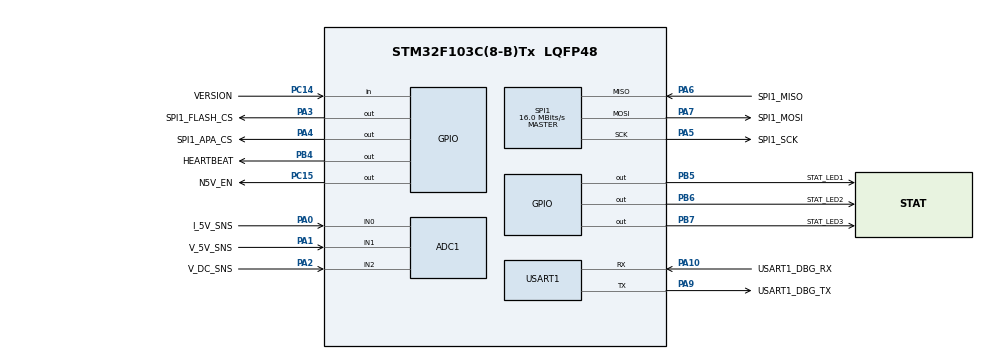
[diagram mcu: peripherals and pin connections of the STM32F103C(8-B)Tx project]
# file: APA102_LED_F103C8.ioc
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Mcu.Family=STM32F1
Dma.SPI1_TX.1.Priority=DMA_PRIORITY_HIGH
PA6.Mode=Full_Duplex_Master
SPI1.VirtualType=VM_MASTER
PA14.GPIO_Label=SWD_CLK
PA3.GPIO_PuPd=GPIO_NOPULL
Dma.SPI1_TX.1.PeriphInc=DMA_PINC_DISABLE
PA6.GPIO_Label=SPI1_MISO
PB6.GPIO_Label=STAT_LED2
PA3.GPIO_Speed=GPIO_SPEED_FREQ_HIGH
PC15-OSC32_OUT.GPIO_Label=N5V_EN
RCC.SYSCLKSource=RCC_SYSCLKSOURCE_PLLCLK
ProjectManager.StackSize=0x400
NVIC.DMA1_Channel3_IRQn=true\:0\:0\:false\:false\:true\:false\:true
Dma.SPI1_RX.0.Direction=DMA_PERIPH_TO_MEMORY
SPI1.Direction=SPI_DIRECTION_2LINES
RCC.HCLKFreq_Value=64000000
RCC.APB2TimFreq_Value=64000000
PB6.Signal=GPIO_Output
ADC1.Channel-2\#ChannelRegularConversion=ADC_CHANNEL_2
PB5.PinState=GPIO_PIN_SET
SPI1.CalculateBaudRate=16.0 MBits/s
RCC.AHBFreq_Value=64000000
Dma.SPI1_TX.1.PeriphDataAlignment=DMA_PDATAALIGN_BYTE
ADC1.Channel-0\#ChannelRegularConversion=ADC_CHANNEL_0
PA4.GPIO_PuPd=GPIO_NOPULL
PB3.Mode=Trace_Asynchronous_SW
RCC.PLLMUL=RCC_PLL_MUL16
PA4.GPIO_Speed=GPIO_SPEED_FREQ_HIGH
Dma.SPI1_RX.0.PeriphInc=DMA_PINC_DISABLE
ADC1.Rank-2\#ChannelRegularConversion=3
Dma.ADC1.2.MemDataAlignment=DMA_MDATAALIGN_HALFWORD
Dma.SPI1_TX.1.Mode=DMA_NORMAL
PA14.Mode=Trace_Asynchronous_SW
PA10.GPIO_Label=USART1_DBG_RX
Dma.ADC1.2.Direction=DMA_PERIPH_TO_MEMORY
PB7.Signal=GPIO_Output
PC15-OSC32_OUT.PinState=GPIO_PIN_SET
ADC1.SamplingTime-0\#ChannelRegularConversion=ADC_SAMPLETIME_55CYCLES_5
PB7.PinState=GPIO_PIN_SET
PB7.GPIO_Label=STAT_LED3
Mcu.Package=LQFP48
PA6.Signal=SPI1_MISO
PA2.GPIO_Label=V_DC_SNS
PB6.GPIO_ModeDefaultOutputPP=GPIO_MODE_OUTPUT_PP
PA10.Signal=USART1_RX
PA4.GPIO_ModeDefaultOutputPP=GPIO_MODE_OUTPUT_PP
PB5.GPIO_Speed=GPIO_SPEED_FREQ_MEDIUM
PB5.GPIO_Label=STAT_LED1
Dma.Request2=ADC1
Dma.Request1=SPI1_TX
RCC.APB1TimFreq_Value=64000000
PC14-OSC32_IN.GPIO_Label=VERSION
PC15-OSC32_OUT.GPIO_Speed=GPIO_SPEED_FREQ_MEDIUM
NVIC.USART1_IRQn=true\:0\:0\:false\:false\:true\:true\:true
Dma.Request0=SPI1_RX
SPI1.BaudRatePrescaler=SPI_BAUDRATEPRESCALER_4
PB4.PinState=GPIO_PIN_SET
PA4.GPIO_Label=SPI1_APA_CS
Dma.SPI1_TX.1.Instance=DMA1_Channel3
PB4.Signal=GPIO_Output
Dma.ADC1.2.Mode=DMA_NORMAL
PB4.GPIO_ModeDefaultOutputPP=GPIO_MODE_OUTPUT_PP
PA3.Signal=GPIO_Output
PA5.Mode=Full_Duplex_Master
PB7.GPIO_Speed=GPIO_SPEED_FREQ_MEDIUM
PB3.GPIO_Label=SWD_O
PB7.GPIO_PuPd=GPIO_NOPULL
PB5.GPIO_ModeDefaultOutputPP=GPIO_MODE_OUTPUT_PP
Dma.SPI1_TX.1.MemInc=DMA_MINC_ENABLE
PA3.GPIO_ModeDefaultOutputPP=GPIO_MODE_OUTPUT_PP
ADC1.Rank-0\#ChannelRegularConversion=1
PA7.Mode=Full_Duplex_Master
PA10.Mode=Asynchronous
SH.SharedAnalog_PA0.0=GPIO_Analog
SH.SharedAnalog_PA0.1=ADC1_IN0,IN0
PA9.GPIO_Label=USART1_DBG_TX
Dma.ADC1.2.PeriphDataAlignment=DMA_PDATAALIGN_HALFWORD
PB6.GPIO_PuPd=GPIO_NOPULL
Dma.SPI1_RX.0.Mode=DMA_NORMAL
RCC.APB1CLKDivider=RCC_HCLK_DIV2
PC14-OSC32_IN.Signal=GPIO_Input
Dma.SPI1_TX.1.Direction=DMA_MEMORY_TO_PERIPH
ADC1.SamplingTime-2\#ChannelRegularConversion=ADC_SAMPLETIME_55CYCLES_5
PA0-WKUP.GPIO_Label=I_5V_SNS
PA0-WKUP.Signal=SharedAnalog_PA0
RCC.ADCPresc=RCC_ADCPCLK2_DIV6
PA13.Signal=SYS_JTMS-SWDIO
PA9.Mode=Asynchronous
Dma.SPI1_TX.1.MemDataAlignment=DMA_MDATAALIGN_BYTE
Dma.ADC1.2.MemInc=DMA_MINC_ENABLE
PA4.PinState=GPIO_PIN_SET
NVIC.DMA1_Channel2_IRQn=true\:0\:0\:false\:false\:true\:false\:true
ProjectManager.TargetToolchain=STM32CubeIDE
PA9.Signal=USART1_TX
ADC1.Channel-1\#ChannelRegularConversion=ADC_CHANNEL_1
PB4.GPIO_PuPd=GPIO_NOPULL
RCC.USBFreq_Value=64000000
PC15-OSC32_OUT.Signal=GPIO_Output
PA1.Signal=SharedAnalog_PA1
PA5.Signal=SPI1_SCK
board=custom
PB4.GPIO_Speed=GPIO_SPEED_FREQ_MEDIUM
RCC.APB2Freq_Value=64000000
PB4.GPIO_Label=HEARTBEAT
SPI1.Mode=SPI_MODE_MASTER
PB7.GPIO_ModeDefaultOutputPP=GPIO_MODE_OUTPUT_PP
Dma.SPI1_RX.0.Instance=DMA1_Channel2
SH.SharedAnalog_PA2.0=GPIO_Analog
SH.SharedAnalog_PA2.1=ADC1_IN2,IN2
PA1.GPIO_Label=V_5V_SNS
Dma.SPI1_RX.0.PeriphDataAlignment=DMA_PDATAALIGN_BYTE
Dma.SPI1_RX.0.MemDataAlignment=DMA_MDATAALIGN_BYTE
ADC1.NbrOfConversion=3
PA13.Mode=Trace_Asynchronous_SW
Mcu.Name=STM32F103C(8-B)Tx
Dma.SPI1_RX.0.MemInc=DMA_MINC_ENABLE
PA2.Signal=SharedAnalog_PA2
PA13.GPIO_Label=SWD_IO
Dma.ADC1.2.Instance=DMA1_Channel1
PB3.Signal=SYS_JTDO-TRACESWO
PA4.Signal=GPIO_Output
ADC1.SamplingTime-1\#ChannelRegularConversion=ADC_SAMPLETIME_55CYCLES_5
RCC.SYSCLKFreq_VALUE=64000000
Dma.ADC1.2.Priority=DMA_PRIORITY_MEDIUM
PB5.Signal=GPIO_Output
PA7.GPIO_Label=SPI1_MOSI
ADC1.master=1
PA5.GPIO_Label=SPI1_SCK
Dma.ADC1.2.PeriphInc=DMA_PINC_DISABLE
PB5.GPIO_PuPd=GPIO_NOPULL
USART1.VirtualMode=VM_ASYNC
PB6.PinState=GPIO_PIN_SET
ADC1.Rank-1\#ChannelRegularConversion=2
PA14.Signal=SYS_JTCK-SWCLK
ProjectManager.HeapSize=0x200
Dma.SPI1_RX.0.Priority=DMA_PRIORITY_HIGH
SH.SharedAnalog_PA1.1=ADC1_IN1,IN1
NVIC.PriorityGroup=NVIC_PRIORITYGROUP_4
SH.SharedAnalog_PA1.0=GPIO_Analog
ADC1.NbrOfConversionFlag=1
PA3.PinState=GPIO_PIN_SET
PC14-OSC32_IN.GPIO_PuPd=GPIO_PULLDOWN
NVIC.DMA1_Channel1_IRQn=true\:0\:0\:false\:false\:true\:false\:true
PB6.GPIO_Speed=GPIO_SPEED_FREQ_MEDIUM
RCC.APB1Freq_Value=32000000
PA3.GPIO_Label=SPI1_FLASH_CS
PA7.Signal=SPI1_MOSI

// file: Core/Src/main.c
/* USER CODE BEGIN Header */
/**
  ******************************************************************************
  * @file           : main.c
  * @brief          : Main program body
  ******************************************************************************
  * @attention
  *
  * <h2><center>&copy; Copyright (c) 2022 STMicroelectronics.
  * All rights reserved.</center></h2>
  *
  * This software component is licensed by ST under BSD 3-Clause license,
  * the "License"; You may not use this file except in compliance with the
  * License. You may obtain a copy of the License at:
  *                        opensource.org/licenses/BSD-3-Clause
  *
  ******************************************************************************
  */
/* USER CODE END Header */
#include "main.h"
#include "adc.h"
#include "dma.h"
#include "spi.h"
#include "usart.h"
#include "gpio.h"

void SystemClock_Config(void);

/* USER CODE BEGIN 0 */
int main (void){
	  LL_APB2_GRP1_EnableClock(LL_APB2_GRP1_PERIPH_AFIO);
	  LL_APB1_GRP1_EnableClock(LL_APB1_GRP1_PERIPH_PWR);

	  NVIC_SetPriorityGrouping(NVIC_PRIORITYGROUP_4);
	  LL_GPIO_AF_Remap_SWJ_NOJTAG();

	  SystemClock_Config();

	  MX_GPIO_Init();
	  MX_DMA_Init();
	  MX_SPI1_Init();
	  MX_USART1_UART_Init();
	  MX_ADC1_Init();
	  for(;;){

	  }
}
/* USER CODE END 0 */

void SystemClock_Config(void)
{
  LL_FLASH_SetLatency(LL_FLASH_LATENCY_2);
  while(LL_FLASH_GetLatency()!= LL_FLASH_LATENCY_2)
  {
  }
  LL_RCC_HSI_SetCalibTrimming(16);
  LL_RCC_HSI_Enable();

   /* Wait till HSI is ready */
  while(LL_RCC_HSI_IsReady() != 1)
  {

  }
  LL_RCC_PLL_ConfigDomain_SYS(LL_RCC_PLLSOURCE_HSI_DIV_2, LL_RCC_PLL_MUL_16);
  LL_RCC_PLL_Enable();

   /* Wait till PLL is ready */
  while(LL_RCC_PLL_IsReady() != 1)
  {

  }
  LL_RCC_SetAHBPrescaler(LL_RCC_SYSCLK_DIV_1);
  LL_RCC_SetAPB1Prescaler(LL_RCC_APB1_DIV_2);
  LL_RCC_SetAPB2Prescaler(LL_RCC_APB2_DIV_1);
  LL_RCC_SetSysClkSource(LL_RCC_SYS_CLKSOURCE_PLL);

   /* Wait till System clock is ready */
  while(LL_RCC_GetSysClkSource() != LL_RCC_SYS_CLKSOURCE_STATUS_PLL)
  {

  }
  LL_Init1msTick(64000000);
  LL_SetSystemCoreClock(64000000);
  LL_RCC_SetADCClockSource(LL_RCC_ADC_CLKSRC_PCLK2_DIV_6);
}

void Error_Handler(void)
{
  __disable_irq();
  while (1)
  {
  }
}

/************************ (C) COPYRIGHT STMicroelectronics *****END OF FILE****/
